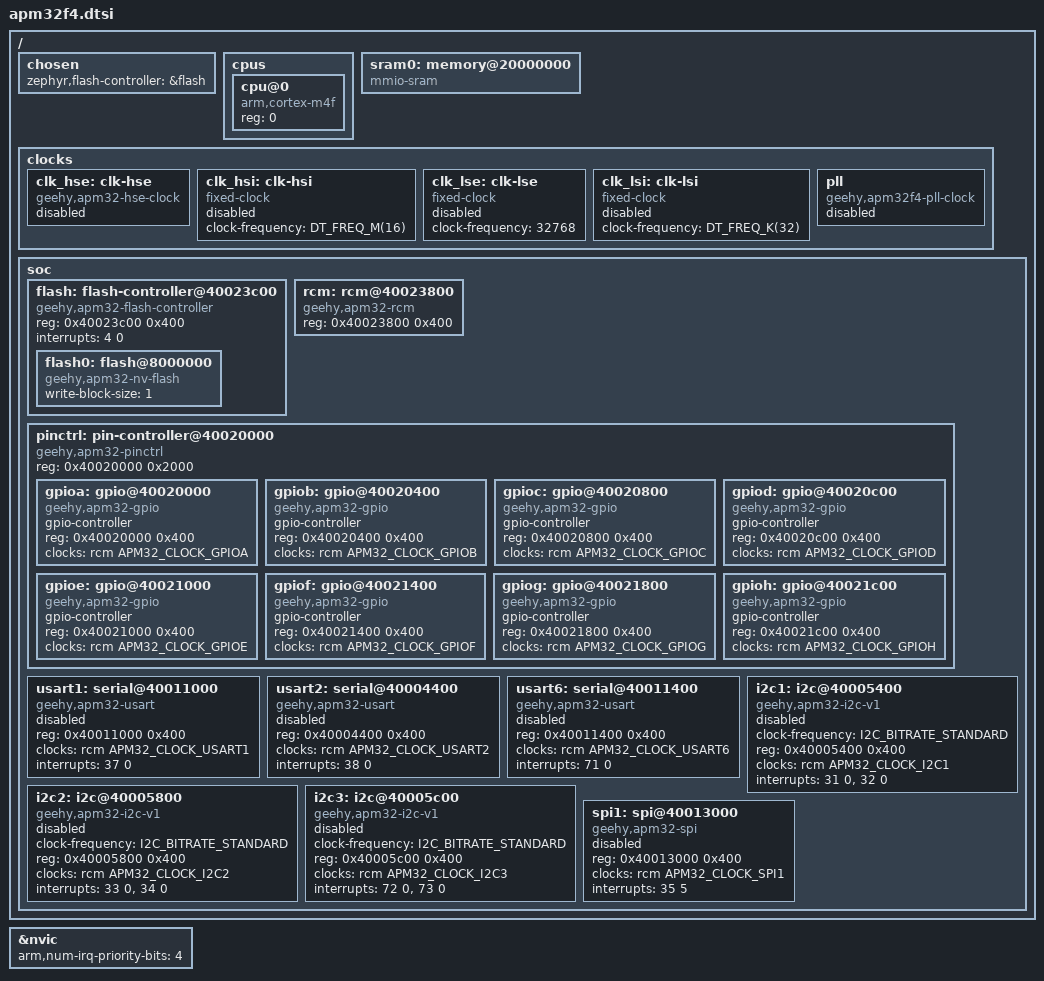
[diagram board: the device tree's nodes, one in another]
/*
 * Copyright (c) 2023, Quincy.W <wangqyfm@foxmail.com>
 * SPDX-License-Identifier: Apache-2.0
 */

#include <arm/armv7-m.dtsi>
#include <zephyr/dt-bindings/adc/adc.h>
#include <zephyr/dt-bindings/i2c/i2c.h>
#include <zephyr/dt-bindings/gpio/gpio.h>
#include <zephyr/dt-bindings/pwm/pwm.h>
#include <zephyr/dt-bindings/clock/apm32_clock_f4.h>

/*
#include <zephyr/dt-bindings/pwm/apm32_pwm.h>
#include <zephyr/dt-bindings/dma/apm32_dma.h>
#include <zephyr/dt-bindings/adc/apm32f4_adc.h>
#include <zephyr/dt-bindings/reset/apm32f2_4_7_reset.h>
*/

#include <freq.h>

/ {
	chosen {
		zephyr,flash-controller = &flash;
	};

	cpus {
		#address-cells = <1>;
		#size-cells = <0>;

		cpu@0 {
			device_type = "cpu";
			compatible = "arm,cortex-m4f";
			reg = <0>;
		};
	};

	sram0: memory@20000000 {
		compatible = "mmio-sram";
	};

	clocks {
		clk_hse: clk-hse {
			#clock-cells = <0>;
			compatible = "geehy,apm32-hse-clock";
			status = "disabled";
		};

		clk_hsi: clk-hsi {
			#clock-cells = <0>;
			compatible = "fixed-clock";
			clock-frequency = <DT_FREQ_M(16)>;
			status = "disabled";
		};

		clk_lse: clk-lse {
			#clock-cells = <0>;
			compatible = "fixed-clock";
			clock-frequency = <32768>;
			status = "disabled";
		};

		clk_lsi: clk-lsi {
			#clock-cells = <0>;
			compatible = "fixed-clock";
			clock-frequency = <DT_FREQ_K(32)>;
			status = "disabled";
		};

		pll: pll {
			#clock-cells = <0>;
			compatible = "geehy,apm32f4-pll-clock";
			status = "disabled";
		};
	};

	soc {
		flash: flash-controller@40023c00 {
			compatible = "geehy,apm32-flash-controller", "geehy,apm32f4-flash-controller";
			reg = <0x40023c00 0x400>;
			interrupts = <4 0>;

			#address-cells = <1>;
			#size-cells = <1>;

			flash0: flash@8000000 {
				compatible = "geehy,apm32-nv-flash", "soc-nv-flash";

				write-block-size = <1>;
			};
		};

		rcm: rcm@40023800 {
			compatible = "geehy,apm32-rcm";
			#clock-cells = <1>;
			reg = <0x40023800 0x400>;
		};

		pinctrl: pin-controller@40020000 {
			compatible = "geehy,apm32-pinctrl";
			#address-cells = <1>;
			#size-cells = <1>;
			reg = <0x40020000 0x2000>;

			gpioa: gpio@40020000 {
				compatible = "geehy,apm32-gpio";
				gpio-controller;
				#gpio-cells = <2>;
				reg = <0x40020000 0x400>;
				clocks = <&rcm APM32_CLOCK_GPIOA>;
			};

			gpiob: gpio@40020400 {
				compatible = "geehy,apm32-gpio";
				gpio-controller;
				#gpio-cells = <2>;
				reg = <0x40020400 0x400>;
				clocks = <&rcm APM32_CLOCK_GPIOB>;
			};

			gpioc: gpio@40020800 {
				compatible = "geehy,apm32-gpio";
				gpio-controller;
				#gpio-cells = <2>;
				reg = <0x40020800 0x400>;
				clocks = <&rcm APM32_CLOCK_GPIOC>;
			};

			gpiod: gpio@40020c00 {
				compatible = "geehy,apm32-gpio";
				gpio-controller;
				#gpio-cells = <2>;
				reg = <0x40020c00 0x400>;
				clocks = <&rcm APM32_CLOCK_GPIOD>;
			};

			gpioe: gpio@40021000 {
				compatible = "geehy,apm32-gpio";
				gpio-controller;
				#gpio-cells = <2>;
				reg = <0x40021000 0x400>;
				clocks = <&rcm APM32_CLOCK_GPIOE>;
			};

			gpiof: gpio@40021400 {
				compatible = "geehy,apm32-gpio";
				gpio-controller;
				#gpio-cells = <2>;
				reg = <0x40021400 0x400>;
				clocks = <&rcm APM32_CLOCK_GPIOF>;
			};

			gpiog: gpio@40021800 {
				compatible = "geehy,apm32-gpio";
				gpio-controller;
				#gpio-cells = <2>;
				reg = <0x40021800 0x400>;
				clocks = <&rcm APM32_CLOCK_GPIOG>;
			};

			gpioh: gpio@40021c00 {
				compatible = "geehy,apm32-gpio";
				gpio-controller;
				#gpio-cells = <2>;
				reg = <0x40021c00 0x400>;
				clocks = <&rcm APM32_CLOCK_GPIOH>;
			};
		};

		usart1: serial@40011000 {
			compatible = "geehy,apm32-usart", "geehy,apm32-uart";
			reg = <0x40011000 0x400>;
			clocks = <&rcm APM32_CLOCK_USART1>;
			interrupts = <37 0>;
			status = "disabled";
		};

		usart2: serial@40004400 {
			compatible = "geehy,apm32-usart", "geehy,apm32-uart";
			reg = <0x40004400 0x400>;
			clocks = <&rcm APM32_CLOCK_USART2>;
			interrupts = <38 0>;
			status = "disabled";
		};

		usart6: serial@40011400 {
			compatible = "geehy,apm32-usart", "geehy,apm32-uart";
			reg = <0x40011400 0x400>;
			clocks = <&rcm APM32_CLOCK_USART6>;
			interrupts = <71 0>;
			status = "disabled";
		};

		i2c1: i2c@40005400 {
			compatible = "geehy,apm32-i2c-v1";
			clock-frequency = <I2C_BITRATE_STANDARD>;
			#address-cells = <1>;
			#size-cells = <0>;
			reg = <0x40005400 0x400>;
			clocks = <&rcm APM32_CLOCK_I2C1>;
			interrupts = <31 0>, <32 0>;
			interrupt-names = "event", "error";
			status = "disabled";
		};

		i2c2: i2c@40005800 {
			compatible = "geehy,apm32-i2c-v1";
			clock-frequency = <I2C_BITRATE_STANDARD>;
			#address-cells = <1>;
			#size-cells = <0>;
			reg = <0x40005800 0x400>;
			clocks = <&rcm APM32_CLOCK_I2C2>;
			interrupts = <33 0>, <34 0>;
			interrupt-names = "event", "error";
			status = "disabled";
		};

		i2c3: i2c@40005c00 {
			compatible = "geehy,apm32-i2c-v1";
			clock-frequency = <I2C_BITRATE_STANDARD>;
			#address-cells = <1>;
			#size-cells = <0>;
			reg = <0x40005c00 0x400>;
			clocks = <&rcm APM32_CLOCK_I2C3>;
			interrupts = <72 0>, <73 0>;
			interrupt-names = "event", "error";
			status = "disabled";
		};

		spi1: spi@40013000 {
			compatible = "geehy,apm32-spi";
			#address-cells = <1>;
			#size-cells = <0>;
			reg = <0x40013000 0x400>;
			clocks = <&rcm APM32_CLOCK_SPI1>;
			interrupts = <35 5>;
			status = "disabled";
		};
	};
};

&nvic {
	arm,num-irq-priority-bits = <4>;
};
